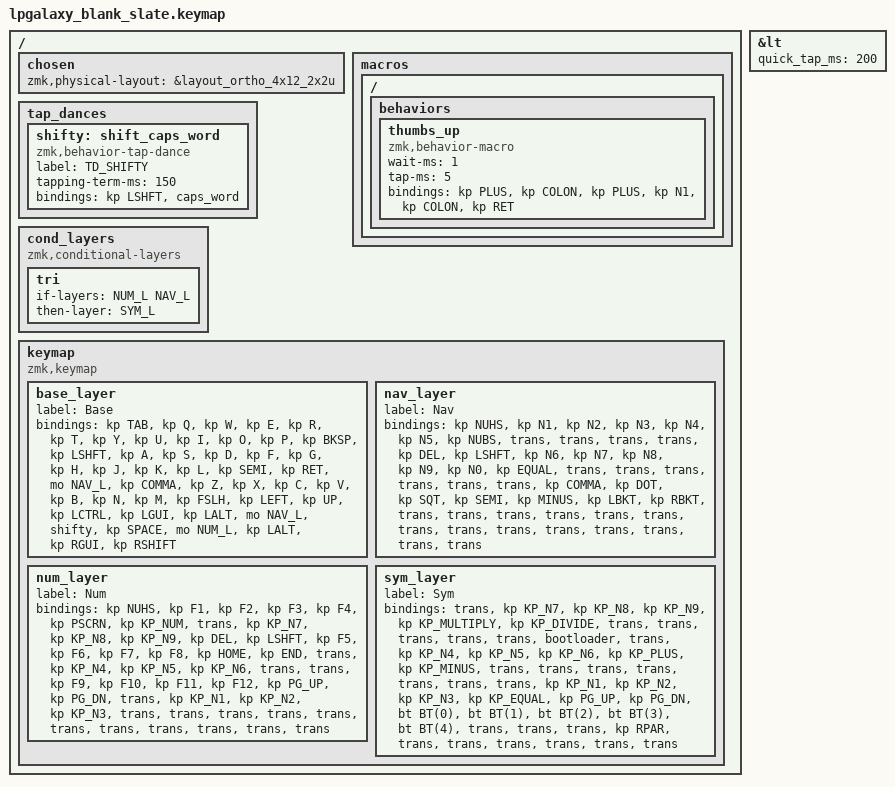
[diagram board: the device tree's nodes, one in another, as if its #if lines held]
/*
 * Copyright (c) 2022 Pete Johanson
 *
 * SPDX-License-Identifier: MIT
 */

#include <behaviors.dtsi>
#include <dt-bindings/zmk/keys.h>
#include <dt-bindings/zmk/bt.h>
#include <dt-bindings/zmk/outputs.h>

#define QWERTY_BASE 1

// #define TBLE_ORTHO   1
#define TBLE_MIT     1
// #define TBLE_DUAL_2U 1

#define NAV_L 1
#define NUM_L 2
#define SYM_L 3

// Using layer taps on thumbs, having quick tap as well helps w/ repeating space/backspace
&lt { quick_tap_ms = <200>; };

#define BT(n) BT_SEL n

/ {
    chosen {
       zmk,physical-layout =
#ifdef TBLE_DUAL_2U
                       &layout_ortho_4x12_2x2u;
#elif defined(TBLE_MIT)
                       &layout_ortho_4x12_1x2u;
#else
                       &layout_ortho_4x12_all1u;
#endif
    };

    macros {
      ZMK_MACRO(thumbs_up,
		wait-ms = <1>;
		tap-ms = <5>;
                bindings = <&kp PLUS &kp COLON &kp PLUS &kp N1 &kp COLON &kp RET>;
		)
    };
    
    tap_dances {
    	shifty: shift_caps_word {
		compatible = "zmk,behavior-tap-dance";
		label = "TD_SHIFTY";
		#binding-cells = <0>;
		tapping-term-ms = <150>;
		bindings = <&kp LSHFT>, <&caps_word>;
	};
    };

// Conditional layer only when we have less thumb keys
#ifdef TBLE_DUAL_2U
    cond_layers {
        compatible = "zmk,conditional-layers";
	tri {
	    if-layers = <NUM_L NAV_L>;
	    then-layer = <SYM_L>;
        };
    };
#endif

    keymap {
        compatible = "zmk,keymap";

        base_layer {
            label = "Base";
            bindings = <
#ifdef QWERTY_BASE
 &kp TAB    &kp Q      &kp W      &kp E       &kp R          &kp T          &kp Y            &kp U          &kp I       &kp O      &kp P         &kp BKSP
 &kp LSHFT  &kp A      &kp S      &kp D       &kp F          &kp G          &kp H            &kp J          &kp K       &kp L      &kp SEMI      &kp RET
 &mo NAV_L  &kp COMMA  &kp Z      &kp X       &kp C          &kp V          &kp B            &kp N          &kp M       &kp FSLH   &kp LEFT      &kp UP
#else
 &kp TAB    &kp Q      &kp W      &kp E       &kp R          &kp T          &kp Y            &kp U          &kp I       &kp O      &kp P         &kp BKSP
 &kp LSHFT  &kp A      &kp S      &kp D       &kp F          &kp G          &kp H            &kp J          &kp K       &kp L      &kp SEMI      &kp RET
 &mo NAV_L  &kp COMMA  &kp Z      &kp X       &kp C          &kp V          &kp B            &kp N          &kp M       &kp FSLH   &kp LEFT      &kp UP
#endif
#ifdef TBLE_DUAL_2U
 &kp LCTRL  &kp LGUI   &kp LALT   &mo NAV_L         &shifty                        &kp SPACE                &mo NUM_L   &kp LALT   &kp RGUI      &kp RSHIFT
#elif defined(TBLE_MIT)
 &kp LCTRL  &kp ESC    &kp LGUI   &kp LALT    &mo SYM_L          &kp SPACE                   &mo NUM_L      &kp DOT     &kp SQT    &kp DOWN      &kp RIGHT
#else
 &kp LCTRL  &kp ESC   &kp LGUI  &kp LALT    &mo NAV_L      &kp SPACE      &kp RET          &mo NUM_L      &kp LEFT    &kp UP     &kp DOWN      &kp RIGHT
#endif
            >;
        };

        nav_layer {
            label = "Nav";
            bindings = <
&kp NUHS   &kp N1     &kp N2     &kp N3      &kp N4         &kp N5       &kp NUBS     &trans         &trans      &trans     &trans     &kp DEL
&kp LSHFT  &kp N6     &kp N7     &kp N8      &kp N9         &kp N0       &kp EQUAL    &trans         &trans      &trans     &trans     &trans
&trans     &kp COMMA  &kp DOT    &kp SQT     &kp SEMI       &kp MINUS    &kp LBKT     &kp RBKT       &trans      &trans     &trans     &trans
#ifdef TBLE_DUAL_2U
&trans  &trans        &trans     &trans              &trans                    &trans                &trans      &trans     &trans     &trans
#elif defined(TBLE_MIT)
&kp LCTRL  &trans        &trans     &trans      &trans                &trans             &trans      &trans   &trans &trans &trans
#else
&trans  &trans        &trans     &trans      &trans          &trans       &trans    &trans           &trans      &trans     &trans     &trans
#endif
            >;
        };

        num_layer {
            label = "Num";
            bindings = <
&kp NUHS   &kp F1     &kp F2     &kp F3      &kp F4         &kp PSCRN    &kp KP_NUM    &trans     &kp KP_N7     &kp KP_N8     &kp KP_N9          &kp DEL
&kp LSHFT  &kp F5     &kp F6     &kp F7      &kp F8         &kp HOME     &kp END       &trans     &kp KP_N4     &kp KP_N5     &kp KP_N6          &trans
&trans     &kp F9     &kp F10    &kp F11     &kp F12        &kp PG_UP    &kp PG_DN     &trans     &kp KP_N1     &kp KP_N2     &kp KP_N3          &trans
#ifdef TBLE_DUAL_2U
&trans  &trans        &trans     &trans              &trans                    &trans                &trans        &trans        &trans     &trans
#elif defined(TBLE_MIT)
&kp LCTRL  &trans      &trans    &trans      &trans                &trans              &trans     &trans        &kp KP_N0     &kp KP_DOT    &trans
#else
&trans  &trans        &trans     &trans      &trans          &trans       &trans    &trans           &trans      &trans     &trans     &trans
#endif
            >;
        };

        sym_layer {
            label = "Sym";
            bindings = <
&trans     &kp KP_N7     &kp KP_N8     &kp KP_N9    &kp KP_MULTIPLY  &kp KP_DIVIDE &trans     &trans    &trans       &trans       &trans     &bootloader
&trans     &kp KP_N4     &kp KP_N5     &kp KP_N6    &kp KP_PLUS      &kp KP_MINUS  &trans     &trans    &trans       &trans       &trans     &trans
&trans     &kp KP_N1     &kp KP_N2     &kp KP_N3    &kp KP_EQUAL     &kp PG_UP     &kp PG_DN  &bt BT(0) &bt BT(1)    &bt BT(2)    &bt BT(3)  &bt BT(4)
#ifdef TBLE_DUAL_2U
&trans &trans        &trans     &kp RPAR                &trans                    &trans       &trans         &trans &trans &trans
#elif defined(TBLE_MIT)
&kp LCTRL  &kp KP_COMMA  &kp KP_N0     &kp RPAR        &trans                &trans             &trans      &trans   &trans &trans &bt BT_CLR
#else
&trans &trans        &trans     &kp KP_DOT        &trans          &trans       &trans    &trans  &trans         &trans &trans &trans
#endif
            >;
        };


    };
};

